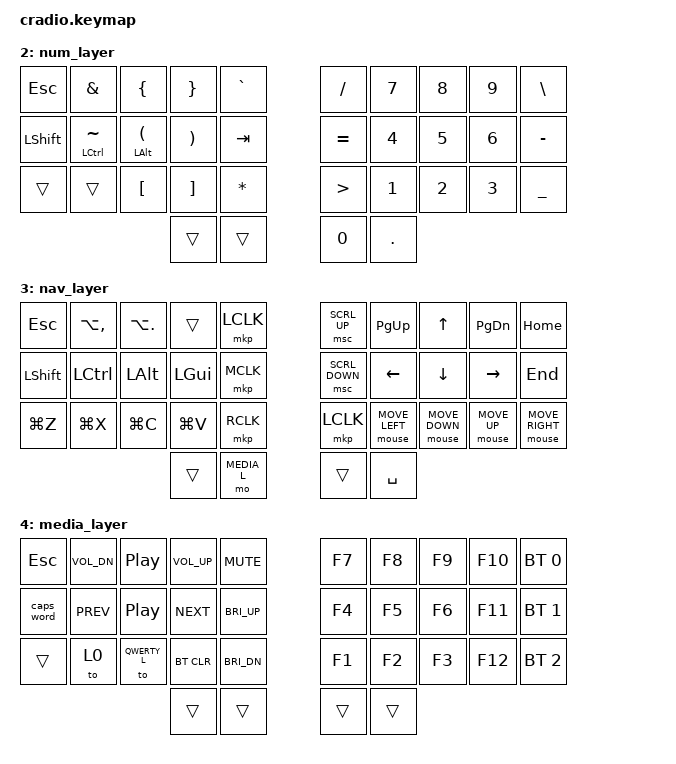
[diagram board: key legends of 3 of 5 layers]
// Copyright (c) 2022 The ZMK Contributors
// SPDX-License-Identifier: MIT

#include <behaviors.dtsi>
#include <dt-bindings/zmk/keys.h>
#include <dt-bindings/zmk/bt.h>

#define ZMK_POINTING_DEFAULT_MOVE_VAL 1500  // default: 600
#define ZMK_POINTING_DEFAULT_SCRL_VAL 20    // default: 10

#include <dt-bindings/zmk/pointing.h>

#define QWERTY_L 1
#define SYM_L 2
#define NAV_L 3
#define MEDIA_L 4

// Home row mods macro
// An exception is made for the LEFT SHIFT, which includes the Y in the
// hold-trigger-key-position. Technically on the other hand, but handy to
// be able to type this single handedly.
#define HRML(k1,k2,k3,k4) &stl LSHFT k1 &htl LCTRL k2  &htl LALT k3  &htl LGUI k4
#define HRMR(k1,k2,k3,k4) &htr RGUI k1  &htr RALT  k2  &htr RCTRL k3 &htr RSHFT k4

/ {
    behaviors {
        stl: shift_tap_left {
            compatible = "zmk,behavior-hold-tap";
            #binding-cells = <2>;
            flavor = "balanced";
            tapping-term-ms = <200>;
            quick-tap-ms = <200>;
            require-prior-idle-ms = <100>;
            bindings = <&kp>, <&kp>;
	    hold-trigger-key-positions = <4 5 6 7 8 9 15 16 17 18 19 25 26 27 28 29>;
	    hold-trigger-on-release;
	    };
        htl: hold_tap_left {
            compatible = "zmk,behavior-hold-tap";
            #binding-cells = <2>;
            flavor = "balanced";
            tapping-term-ms = <200>;
            quick-tap-ms = <200>;
            require-prior-idle-ms = <100>;
            bindings = <&kp>, <&kp>;
	    hold-trigger-key-positions = <5 6 7 8 9 15 16 17 18 19 25 26 27 28 29 30 31 32 33>;
	    hold-trigger-on-release;
	    };
        htr: hold_tap_right {
            compatible = "zmk,behavior-hold-tap";
            #binding-cells = <2>;
            flavor = "balanced";
            tapping-term-ms = <200>;
            quick-tap-ms = <200>;
            require-prior-idle-ms = <100>;
            bindings = <&kp>, <&kp>;
	    hold-trigger-key-positions = <0 1 2 3 4 10 11 12 13 14 20 21 22 23 24 30 31 32 33>;
	    hold-trigger-on-release;
        };
        mouse: mouse_move {
            compatible = "zmk,behavior-input-two-axis";
            time-to-max-speed-ms = <500>;
            acceleration-exponent = <1>;
        };
    };

    keymap {
        compatible = "zmk,keymap";

        default_layer {
            bindings = <
                &kp SQT     &kp COMMA       &kp DOT         &kp P           &kp Y           &kp F           &kp G           &kp C       &kp R       &kp L
                HRML(A,     O,              E,              U)              &kp I           &kp D           HRMR(H,         T,          N,          S)
                &kp SEMI    &kp Q           &kp J           &kp K           &kp X           &kp B           &kp M           &kp W       &kp V       &kp Z
                                                            &mt LCTRL TAB   &lt SYM_L BSPC  &lt NAV_L SPACE &mt LSHFT ENTER
            >;
        };

    	qwerty_layer {
	        bindings = <
	            &kp Q       &kp W           &kp E           &kp R           &kp T           &kp Y           &kp U           &kp I       &kp O       &kp P
		        HRML(A,     S,              D,              F)              &kp G           &kp H           HRMR(J,         K,          L,          SEMI)
		        &kp Z       &kp X           &kp C           &kp V           &kp B           &kp N           &kp M           &kp COMMA   &kp DOT     &kp FSLH
		                                                    &mt LCTRL TAB   &lt SYM_L BSPC  &lt NAV_L SPACE &mt LSHFT ENTER
	        >;
	    };

        num_layer {
            bindings = <
                &kp ESC     &kp AMPS        &kp LBRC        &kp RBRC        &kp GRAVE       &kp FSLH        &kp N7          &kp N8      &kp N9      &kp BSLH
                &kp LSHFT   &htl LCTRL TILDE &htl LALT LPAR   &kp RPAR        &kp TAB         &kp EQUAL       &kp N4          &kp N5      &kp N6      &kp MINUS
                &trans      &trans	        &kp LBKT        &kp RBKT        &kp STAR        &kp GT          &kp N1          &kp N2      &kp N3      &kp UNDER
                                                            &trans          &trans          &kp N0          &kp DOT
            >;
        };

	    nav_layer {
            bindings = <
                &kp ESC     &kp LA(COMMA)   &kp LA(DOT)     &trans          &mkp LCLK          &msc SCRL_UP    &kp PG_UP         &kp UP           &kp PG_DN      &kp HOME
                &kp LSHFT   &kp LCTRL       &kp LALT        &kp LGUI        &mkp MCLK          &msc SCRL_DOWN  &kp LEFT          &kp DOWN         &kp RIGHT      &kp END
                &kp LG(Z)   &kp LG(X)       &kp LG(C)       &kp LG(V)       &mkp RCLK          &mkp LCLK       &mouse MOVE_LEFT  &mouse MOVE_DOWN &mouse MOVE_UP &mouse MOVE_RIGHT
                                                            &trans          &mo MEDIA_L        &trans          &kp SPACE
            >;
        };

	    media_layer {
            bindings = <
                &kp ESC     &kp C_VOL_DN    &kp C_PP        &kp C_VOL_UP    &kp C_MUTE      &kp F7          &kp F8          &kp F9      &kp F10     &bt BT_SEL 0
                &caps_word  &kp C_PREV      &kp C_PP        &kp C_NEXT      &kp C_BRI_UP    &kp F4          &kp F5          &kp F6      &kp F11     &bt BT_SEL 1
                &trans      &to 0           &to QWERTY_L    &bt BT_CLR      &kp C_BRI_DN    &kp F1          &kp F2          &kp F3      &kp F12     &bt BT_SEL 2
                                                            &trans          &trans          &trans          &trans
            >;
        };
    };
};
